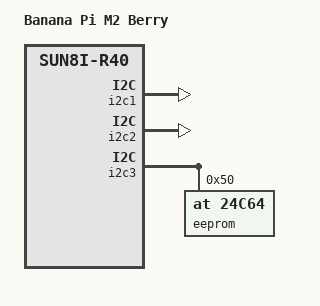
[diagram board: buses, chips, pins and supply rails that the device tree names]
/dts-v1/;
/plugin/;

/ {
	compatible = "sun8i-r40";

	fragment@0 {
		target-path = "/";
		__overlay__ {
			model = "Banana Pi M2 Berry";
			compatible = "sinovoip,bpi-m2-berry", "sinovoip,bpi-m2-ultraallwinner,sun8i-r40", "allwinner,sun8i-r40";
		};
	};

	fragment@1 {
		target = <&i2c1>;
		__overlay__ {
			status = "okay";
		};
	};

	fragment@2 {
		target = <&i2c2>;
		__overlay__ {
			status = "okay";
		};
	};

	fragment@3 {
		target = <&i2c3>;
		__overlay__ {
			status = "okay";
			eeprom@50 {
				compatible = "at,24c64";
				pagesize = <32>;
				reg = <0x50>;
			};
		};
	};
};
